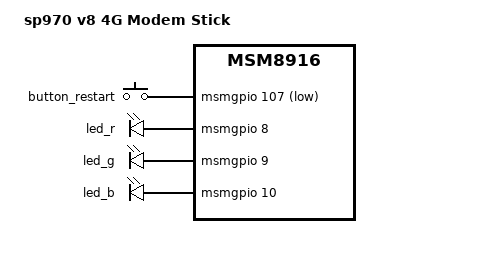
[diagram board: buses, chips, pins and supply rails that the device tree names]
// SPDX-License-Identifier: GPL-2.0-only

/dts-v1/;

#include "msm8916-ufi.dtsi"

/ {
	model = "sp970 v8 4G Modem Stick";
	compatible = "gexing,sp970-v8", "qcom,msm8916";
};

&button_restart {
	gpios = <&msmgpio 107 GPIO_ACTIVE_LOW>;
};

&led_r {
	gpios = <&msmgpio 8 GPIO_ACTIVE_HIGH>;
};

&led_g {
	gpios = <&msmgpio 9 GPIO_ACTIVE_HIGH>;
};

&led_b {
	gpios = <&msmgpio 10 GPIO_ACTIVE_HIGH>;
};

&button_default {
	pins = "gpio107";
	bias-pull-up;
};

&gpio_leds_default {
	pins = "gpio8", "gpio9", "gpio10";
};
